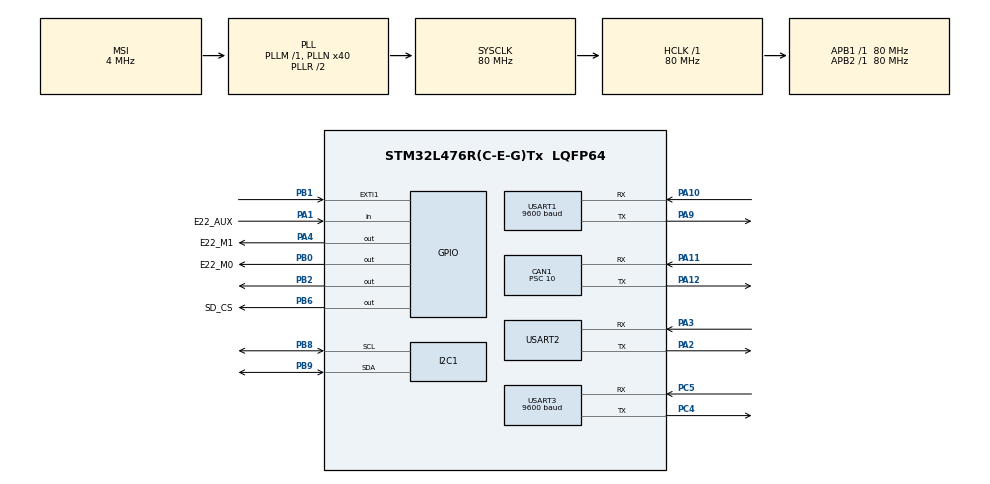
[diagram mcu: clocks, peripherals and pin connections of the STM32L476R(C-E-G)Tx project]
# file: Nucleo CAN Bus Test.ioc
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CAN1.ABOM=ENABLE
CAN1.BS1=CAN_BS1_13TQ
CAN1.BS2=CAN_BS2_2TQ
CAN1.CalculateBaudRate=500000
CAN1.CalculateTimeBit=2000
CAN1.CalculateTimeQuantum=125.0
CAN1.Prescaler=10
Dma.Request0=USART1_TX
Dma.USART1_TX.0.Direction=DMA_MEMORY_TO_PERIPH
Dma.USART1_TX.0.Instance=DMA1_Channel4
Dma.USART1_TX.0.MemDataAlignment=DMA_MDATAALIGN_BYTE
Dma.USART1_TX.0.MemInc=DMA_MINC_ENABLE
Dma.USART1_TX.0.Mode=DMA_NORMAL
Dma.USART1_TX.0.PeriphDataAlignment=DMA_PDATAALIGN_BYTE
Dma.USART1_TX.0.PeriphInc=DMA_PINC_DISABLE
Dma.USART1_TX.0.Priority=DMA_PRIORITY_LOW
I2C1.Timing=0x10D19CE4
Mcu.Family=STM32L4
Mcu.Name=STM32L476R(C-E-G)Tx
Mcu.Package=LQFP64
NVIC.CAN1_RX0_IRQn=true\:0\:0\:false\:false\:true\:true\:true\:true
NVIC.DMA1_Channel4_IRQn=true\:1\:0\:false\:false\:true\:false\:false\:true
NVIC.EXTI1_IRQn=true\:0\:0\:false\:false\:true\:true\:true\:true
NVIC.PriorityGroup=NVIC_PRIORITYGROUP_4
NVIC.USART1_IRQn=true\:1\:0\:false\:false\:true\:false\:false\:true
NVIC.USART3_IRQn=true\:0\:0\:false\:false\:true\:true\:true\:true
PA1.GPIO_Label=E22_AUX
PA1.GPIO_PuPd=GPIO_PULLUP
PA1.Signal=GPIO_Input
PA10.Mode=Asynchronous
PA10.Signal=USART1_RX
PA11.Mode=CAN_Activate
PA11.Signal=CAN1_RX
PA12.Mode=CAN_Activate
PA12.Signal=CAN1_TX
PA2.Mode=Asynchronous
PA2.Signal=USART2_TX
PA3.Mode=Asynchronous
PA3.Signal=USART2_RX
PA4.GPIO_Label=E22_M1
PA4.Signal=GPIO_Output
PA9.Mode=Asynchronous
PA9.Signal=USART1_TX
PB0.GPIO_Label=E22_M0
PB0.Signal=GPIO_Output
PB1.GPIO_ModeDefaultEXTI=GPIO_MODE_IT_FALLING
PB1.GPIO_PuPd=GPIO_PULLUP
PB1.Signal=GPXTI1
PB2.Signal=GPIO_Output
PB6.GPIO_Label=SD_CS
PB6.GPIO_PuPd=GPIO_PULLUP
PB6.PinState=GPIO_PIN_SET
PB6.Signal=GPIO_Output
PB8.Mode=I2C
PB8.Signal=I2C1_SCL
PB9.Mode=I2C
PB9.Signal=I2C1_SDA
PC4.Mode=Asynchronous
PC4.Signal=USART3_TX
PC5.Mode=Asynchronous
PC5.Signal=USART3_RX
ProjectManager.HeapSize=0x200
ProjectManager.StackSize=0x400
ProjectManager.TargetToolchain=STM32CubeIDE
RCC.AHBFreq_Value=80000000
RCC.APB1Freq_Value=80000000
RCC.APB1TimFreq_Value=80000000
RCC.APB2Freq_Value=80000000
RCC.APB2TimFreq_Value=80000000
RCC.CortexFreq_Value=80000000
RCC.HCLKFreq_Value=80000000
RCC.HSE_VALUE=8000000
RCC.HSI_VALUE=16000000
RCC.LSE_VALUE=32768
RCC.MSI_VALUE=4000000
RCC.PLLN=40
RCC.SYSCLKFreq_VALUE=80000000
RCC.SYSCLKSource=RCC_SYSCLKSOURCE_PLLCLK
RCC.VCOOutputFreq_Value=160000000
USART1.BaudRate=9600
USART1.VirtualMode-Asynchronous=VM_ASYNC
USART2.VirtualMode-Asynchronous=VM_ASYNC
USART3.BaudRate=9600
USART3.VirtualMode-Asynchronous=VM_ASYNC
board=custom

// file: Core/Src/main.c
/* USER CODE BEGIN Header */
/**
  ******************************************************************************
  * @file           : main.c
  * @brief          : Telemetry hub - CAN aggregation, LoRa uplink, SD logging
  ******************************************************************************
  * @attention
  *
  * Copyright (c) 2026 STMicroelectronics.
  * All rights reserved.
  *
  * This software is licensed under terms that can be found in the LICENSE file
  * in the root directory of this software component.
  * If no LICENSE file comes with this software, it is provided AS-IS.
  *
  ******************************************************************************
  */
/* USER CODE END Header */
#include "main.h"

/* USER CODE BEGIN Includes */
/* v2 bench test, 2026-08-14: the 1st Bluepill is temporarily standing in for
   node 3 (E-CVT/Motor) on the real CAN bus (node_id.h there is set to 3), so
   the hub must NOT also fabricate node 3 locally - see HUB2_SIMULATE_NODE3's
   comment in telemetry_hub_v2.h.
   NOTE, 2026-08-16: a #define here does NOT work - this file and
   telemetry_hub_v2.c are separate translation units, and the #if that
   matters is evaluated in telemetry_hub_v2.c's own independent preprocessing
   of this same header, which never sees a #define placed here. The actual
   override lives in platformio.ini's build_flags (-D HUB2_SIMULATE_NODE3=0)
   and the CubeIDE project's Preprocessor settings - see HUB2_SIMULATE_NODE3's
   comment in telemetry_hub_v2.h for the full explanation. Set back to 1 (or
   remove the -D) once the stand-in board is off the bus and nothing real has
   replaced it. */
#include "telemetry_hub_v2.h"
/* USER CODE END Includes */

CAN_HandleTypeDef hcan1;

I2C_HandleTypeDef hi2c1;

UART_HandleTypeDef huart1;
UART_HandleTypeDef huart2;
UART_HandleTypeDef huart3;
DMA_HandleTypeDef hdma_usart1_tx;

void SystemClock_Config(void);
static void MX_GPIO_Init(void);
static void MX_DMA_Init(void);
static void MX_CAN1_Init(void);
static void MX_USART2_UART_Init(void);
static void MX_USART1_UART_Init(void);
static void MX_I2C1_Init(void);
static void MX_USART3_UART_Init(void);

int main(void)
{

  /* MCU Configuration--------------------------------------------------------*/

  /* Reset of all peripherals, Initializes the Flash interface and the Systick. */
  HAL_Init();

  /* Configure the system clock */
  SystemClock_Config();

  /* Initialize all configured peripherals */
  MX_GPIO_Init();
  MX_DMA_Init();
  MX_CAN1_Init();
  MX_USART2_UART_Init();
  MX_USART1_UART_Init();
  MX_I2C1_Init();
  MX_USART3_UART_Init();
  /* USER CODE BEGIN 2 */

  /* huart1 -> E22 LoRa module, huart2 -> ST-Link virtual COM port */
  hub2_init(&hcan1, &huart1, &huart2);

  /* USER CODE END 2 */

  /* Infinite loop */
  while (1)
  {

    /* USER CODE BEGIN 3 */
    hub2_task();
  }
  /* USER CODE END 3 */
}

void SystemClock_Config(void)
{
  RCC_OscInitTypeDef RCC_OscInitStruct = {0};
  RCC_ClkInitTypeDef RCC_ClkInitStruct = {0};

  /** Configure the main internal regulator output voltage
  */
  if (HAL_PWREx_ControlVoltageScaling(PWR_REGULATOR_VOLTAGE_SCALE1) != HAL_OK)
  {
    Error_Handler();
  }

  /** Initializes the RCC Oscillators according to the specified parameters
  * in the RCC_OscInitTypeDef structure.
  */
  RCC_OscInitStruct.OscillatorType = RCC_OSCILLATORTYPE_MSI;
  RCC_OscInitStruct.MSIState = RCC_MSI_ON;
  RCC_OscInitStruct.MSICalibrationValue = 0;
  RCC_OscInitStruct.MSIClockRange = RCC_MSIRANGE_6;
  RCC_OscInitStruct.PLL.PLLState = RCC_PLL_ON;
  RCC_OscInitStruct.PLL.PLLSource = RCC_PLLSOURCE_MSI;
  RCC_OscInitStruct.PLL.PLLM = 1;
  RCC_OscInitStruct.PLL.PLLN = 40;
  RCC_OscInitStruct.PLL.PLLP = RCC_PLLP_DIV7;
  RCC_OscInitStruct.PLL.PLLQ = RCC_PLLQ_DIV2;
  RCC_OscInitStruct.PLL.PLLR = RCC_PLLR_DIV2;
  if (HAL_RCC_OscConfig(&RCC_OscInitStruct) != HAL_OK)
  {
    Error_Handler();
  }

  /** Initializes the CPU, AHB and APB buses clocks
  */
  RCC_ClkInitStruct.ClockType = RCC_CLOCKTYPE_HCLK|RCC_CLOCKTYPE_SYSCLK
                              |RCC_CLOCKTYPE_PCLK1|RCC_CLOCKTYPE_PCLK2;
  RCC_ClkInitStruct.SYSCLKSource = RCC_SYSCLKSOURCE_PLLCLK;
  RCC_ClkInitStruct.AHBCLKDivider = RCC_SYSCLK_DIV1;
  RCC_ClkInitStruct.APB1CLKDivider = RCC_HCLK_DIV1;
  RCC_ClkInitStruct.APB2CLKDivider = RCC_HCLK_DIV1;

  if (HAL_RCC_ClockConfig(&RCC_ClkInitStruct, FLASH_LATENCY_4) != HAL_OK)
  {
    Error_Handler();
  }
}

static void MX_CAN1_Init(void)
{

  hcan1.Instance = CAN1;
  hcan1.Init.Prescaler = 10;
  hcan1.Init.Mode = CAN_MODE_NORMAL;
  hcan1.Init.SyncJumpWidth = CAN_SJW_1TQ;
  hcan1.Init.TimeSeg1 = CAN_BS1_13TQ;
  hcan1.Init.TimeSeg2 = CAN_BS2_2TQ;
  hcan1.Init.TimeTriggeredMode = DISABLE;
  hcan1.Init.AutoBusOff = ENABLE;
  hcan1.Init.AutoWakeUp = DISABLE;
  hcan1.Init.AutoRetransmission = DISABLE;
  hcan1.Init.ReceiveFifoLocked = DISABLE;
  hcan1.Init.TransmitFifoPriority = DISABLE;
  if (HAL_CAN_Init(&hcan1) != HAL_OK)
  {
    Error_Handler();
  }

}

static void MX_I2C1_Init(void)
{

  hi2c1.Instance = I2C1;
  hi2c1.Init.Timing = 0x10D19CE4;
  hi2c1.Init.OwnAddress1 = 0;
  hi2c1.Init.AddressingMode = I2C_ADDRESSINGMODE_7BIT;
  hi2c1.Init.DualAddressMode = I2C_DUALADDRESS_DISABLE;
  hi2c1.Init.OwnAddress2 = 0;
  hi2c1.Init.OwnAddress2Masks = I2C_OA2_NOMASK;
  hi2c1.Init.GeneralCallMode = I2C_GENERALCALL_DISABLE;
  hi2c1.Init.NoStretchMode = I2C_NOSTRETCH_DISABLE;
  if (HAL_I2C_Init(&hi2c1) != HAL_OK)
  {
    Error_Handler();
  }

  /** Configure Analogue filter
  */
  if (HAL_I2CEx_ConfigAnalogFilter(&hi2c1, I2C_ANALOGFILTER_ENABLE) != HAL_OK)
  {
    Error_Handler();
  }

  /** Configure Digital filter
  */
  if (HAL_I2CEx_ConfigDigitalFilter(&hi2c1, 0) != HAL_OK)
  {
    Error_Handler();
  }

}

static void MX_USART1_UART_Init(void)
{

  huart1.Instance = USART1;
  huart1.Init.BaudRate = 9600;
  huart1.Init.WordLength = UART_WORDLENGTH_8B;
  huart1.Init.StopBits = UART_STOPBITS_1;
  huart1.Init.Parity = UART_PARITY_NONE;
  huart1.Init.Mode = UART_MODE_TX_RX;
  huart1.Init.HwFlowCtl = UART_HWCONTROL_NONE;
  huart1.Init.OverSampling = UART_OVERSAMPLING_16;
  huart1.Init.OneBitSampling = UART_ONE_BIT_SAMPLE_DISABLE;
  huart1.AdvancedInit.AdvFeatureInit = UART_ADVFEATURE_NO_INIT;
  if (HAL_UART_Init(&huart1) != HAL_OK)
  {
    Error_Handler();
  }

}

static void MX_USART2_UART_Init(void)
{

  huart2.Instance = USART2;
  huart2.Init.BaudRate = 115200;
  huart2.Init.WordLength = UART_WORDLENGTH_8B;
  huart2.Init.StopBits = UART_STOPBITS_1;
  huart2.Init.Parity = UART_PARITY_NONE;
  huart2.Init.Mode = UART_MODE_TX_RX;
  huart2.Init.HwFlowCtl = UART_HWCONTROL_NONE;
  huart2.Init.OverSampling = UART_OVERSAMPLING_16;
  huart2.Init.OneBitSampling = UART_ONE_BIT_SAMPLE_DISABLE;
  huart2.AdvancedInit.AdvFeatureInit = UART_ADVFEATURE_NO_INIT;
  if (HAL_UART_Init(&huart2) != HAL_OK)
  {
    Error_Handler();
  }

}

static void MX_USART3_UART_Init(void)
{

  huart3.Instance = USART3;
  huart3.Init.BaudRate = 9600;
  huart3.Init.WordLength = UART_WORDLENGTH_8B;
  huart3.Init.StopBits = UART_STOPBITS_1;
  huart3.Init.Parity = UART_PARITY_NONE;
  huart3.Init.Mode = UART_MODE_TX_RX;
  huart3.Init.HwFlowCtl = UART_HWCONTROL_NONE;
  huart3.Init.OverSampling = UART_OVERSAMPLING_16;
  huart3.Init.OneBitSampling = UART_ONE_BIT_SAMPLE_DISABLE;
  huart3.AdvancedInit.AdvFeatureInit = UART_ADVFEATURE_NO_INIT;
  if (HAL_UART_Init(&huart3) != HAL_OK)
  {
    Error_Handler();
  }

}

static void MX_DMA_Init(void)
{

  /* DMA controller clock enable */
  __HAL_RCC_DMA1_CLK_ENABLE();

  /* DMA interrupt init */
  /* DMA1_Channel4_IRQn interrupt configuration */
  HAL_NVIC_SetPriority(DMA1_Channel4_IRQn, 1, 0);
  HAL_NVIC_EnableIRQ(DMA1_Channel4_IRQn);

}

static void MX_GPIO_Init(void)
{
  GPIO_InitTypeDef GPIO_InitStruct = {0};

  /* GPIO Ports Clock Enable */
  __HAL_RCC_GPIOA_CLK_ENABLE();
  __HAL_RCC_GPIOC_CLK_ENABLE();
  __HAL_RCC_GPIOB_CLK_ENABLE();

  /*Configure GPIO pin Output Level */
  HAL_GPIO_WritePin(E22_M1_GPIO_Port, E22_M1_Pin, GPIO_PIN_RESET);

  /*Configure GPIO pin Output Level */
  HAL_GPIO_WritePin(GPIOB, E22_M0_Pin|GPIO_PIN_2, GPIO_PIN_RESET);

  /*Configure GPIO pin Output Level */
  HAL_GPIO_WritePin(SD_CS_GPIO_Port, SD_CS_Pin, GPIO_PIN_SET);

  /*Configure GPIO pin : E22_AUX_Pin */
  GPIO_InitStruct.Pin = E22_AUX_Pin;
  GPIO_InitStruct.Mode = GPIO_MODE_INPUT;
  GPIO_InitStruct.Pull = GPIO_PULLUP;
  HAL_GPIO_Init(E22_AUX_GPIO_Port, &GPIO_InitStruct);

  /*Configure GPIO pin : E22_M1_Pin */
  GPIO_InitStruct.Pin = E22_M1_Pin;
  GPIO_InitStruct.Mode = GPIO_MODE_OUTPUT_PP;
  GPIO_InitStruct.Pull = GPIO_NOPULL;
  GPIO_InitStruct.Speed = GPIO_SPEED_FREQ_LOW;
  HAL_GPIO_Init(E22_M1_GPIO_Port, &GPIO_InitStruct);

  /*Configure GPIO pins : E22_M0_Pin PB2 */
  GPIO_InitStruct.Pin = E22_M0_Pin|GPIO_PIN_2;
  GPIO_InitStruct.Mode = GPIO_MODE_OUTPUT_PP;
  GPIO_InitStruct.Pull = GPIO_NOPULL;
  GPIO_InitStruct.Speed = GPIO_SPEED_FREQ_LOW;
  HAL_GPIO_Init(GPIOB, &GPIO_InitStruct);

  /*Configure GPIO pin : PB1 */
  GPIO_InitStruct.Pin = GPIO_PIN_1;
  GPIO_InitStruct.Mode = GPIO_MODE_IT_FALLING;
  GPIO_InitStruct.Pull = GPIO_PULLUP;
  HAL_GPIO_Init(GPIOB, &GPIO_InitStruct);

  /*Configure GPIO pin : SD_CS_Pin */
  GPIO_InitStruct.Pin = SD_CS_Pin;
  GPIO_InitStruct.Mode = GPIO_MODE_OUTPUT_PP;
  GPIO_InitStruct.Pull = GPIO_PULLUP;
  GPIO_InitStruct.Speed = GPIO_SPEED_FREQ_LOW;
  HAL_GPIO_Init(SD_CS_GPIO_Port, &GPIO_InitStruct);

  /* EXTI interrupt init*/
  HAL_NVIC_SetPriority(EXTI1_IRQn, 0, 0);
  HAL_NVIC_EnableIRQ(EXTI1_IRQn);

}

void Error_Handler(void)
{
  __disable_irq();
  while (1)
  {
  }
}
